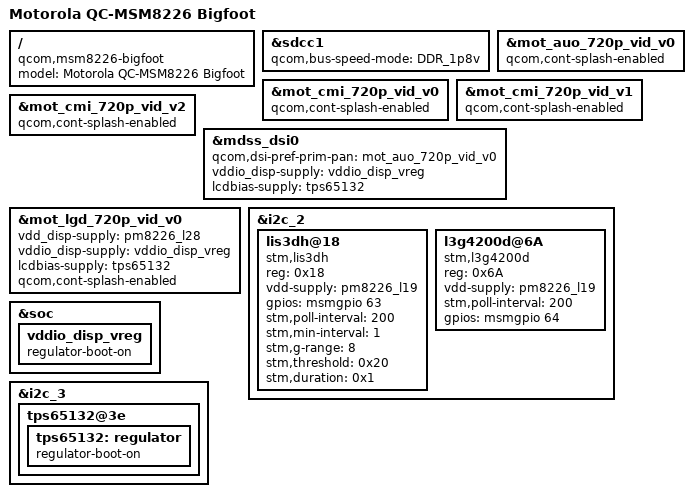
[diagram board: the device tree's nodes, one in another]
/* Copyright (c) 2013, The Linux Foundation. All rights reserved.
 * Copyright (c) 2013 Motorola Mobility LLC
 *
 * This program is free software; you can redistribute it and/or modify
 * it under the terms of the GNU General Public License version 2 and
 * only version 2 as published by the Free Software Foundation.
 *
 * This program is distributed in the hope that it will be useful,
 * but WITHOUT ANY WARRANTY; without even the implied warranty of
 * MERCHANTABILITY or FITNESS FOR A PARTICULAR PURPOSE.  See the
 * GNU General Public License for more details.
 */

/include/ "msm8226-moto-common.dtsi"
/include/ "dsi-panel-mot-auo-720p-video.dtsi"
/include/ "dsi-panel-mot-cmi-720p-video.dtsi"
/include/ "dsi-panel-mot-lgd-720p-video.dtsi"

/ {
	model = "Motorola QC-MSM8226 Bigfoot";
	compatible = "qcom,msm8226-bigfoot",
		     "qcom,msm8226-moto",
		     "qcom,msm8226";
};

&sdcc1 {
	qcom,bus-speed-mode = "DDR_1p8v";
};

&mot_auo_720p_vid_v0 {
	qcom,cont-splash-enabled;
};

&mot_cmi_720p_vid_v0 {
	qcom,cont-splash-enabled;
};

&mot_cmi_720p_vid_v1 {
	qcom,cont-splash-enabled;
};

&mot_cmi_720p_vid_v2 {
	qcom,cont-splash-enabled;
};

&mdss_dsi0 {
	qcom,dsi-pref-prim-pan = <&mot_auo_720p_vid_v0>;
	vddio_disp-supply = <&vddio_disp_vreg>;
	lcdbias-supply = <&tps65132>;
};

&mot_lgd_720p_vid_v0 {
	vdd_disp-supply = <&pm8226_l28>;
	vddio_disp-supply = <&vddio_disp_vreg>;
	lcdbias-supply = <&tps65132>;
	qcom,cont-splash-enabled;
};

&i2c_2 {
	lis3dh@18 {
		compatible = "stm,lis3dh";
		reg = <0x18>;
		vdd-supply = <&pm8226_l19>;
		gpios = <&msmgpio 63 0>; /* IRQ */
		stm,poll-interval = <200>;
		stm,min-interval = <1>;
		stm,g-range = <8>;
		stm,threshold = <0x20>;
		stm,duration = <0x1>;
	};

	l3g4200d@6A {
		compatible = "stm,l3g4200d";
		reg = <0x6A>;
		vdd-supply =  <&pm8226_l19>;
		stm,poll-interval = <200>;
		gpios = <&msmgpio 64 0>; /* DRDY/INT2 */
	};
};

&soc {
       vddio_disp_vreg: vddio_disp_vreg {
               regulator-boot-on;
       };
};

&i2c_3 {
       tps65132@3e {
               tps65132: regulator {
                       regulator-boot-on;
               };
       };
};
